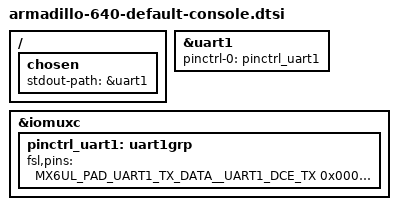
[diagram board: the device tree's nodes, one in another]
/*
 * Copyright (C) 2018 Atmark Techno, Inc. All Rights Reserved.
 *
 * SPDX-License-Identifier: (GPL-2.0 OR MIT)
 */

/ {
	chosen {
		stdout-path = &uart1;
	};
};

&uart1 {
	pinctrl-names = "default";
	pinctrl-0 = <&pinctrl_uart1>;
	status = "okay";
};

&iomuxc {
	pinctrl_uart1: uart1grp {
		fsl,pins = <
			MX6UL_PAD_UART1_TX_DATA__UART1_DCE_TX 0x00008
			MX6UL_PAD_UART1_RX_DATA__UART1_DCE_RX 0x1b0b1
		>;
	};
};
